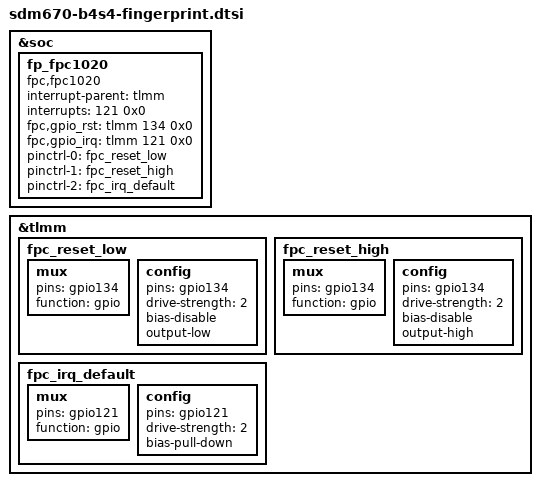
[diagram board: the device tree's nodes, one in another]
/* Copyright (c) 2018, The Linux Foundation. All rights reserved.
 *
 * This program is free software; you can redistribute it and/or modify
 * it under the terms of the GNU General Public License version 2 and
 * only version 2 as published by the Free Software Foundation.
 *
 * This program is distributed in the hope that it will be useful,
 * but WITHOUT ANY WARRANTY; without even the implied warranty of
 * MERCHANTABILITY or FITNESS FOR A PARTICULAR PURPOSE.  See the
 * GNU General Public License for more details.
 */

&soc {
	fp_fpc1020 {
		status ="ok";
		compatible = "fpc,fpc1020";
		interrupt-parent = <&tlmm>;
		interrupts = <121 0x0>;
		fpc,gpio_rst = <&tlmm 134 0x0>;
		fpc,gpio_irq = <&tlmm 121 0x0>;

		pinctrl-names = "fpc1020_reset_reset",
				"fpc1020_reset_active",
				"fpc1020_irq_active";

		pinctrl-0 = <&fpc_reset_low>;
		pinctrl-1 = <&fpc_reset_high>;
		pinctrl-2 = <&fpc_irq_default>;
	};
} ;

&tlmm {
	fpc_reset_low: fpc_reset_low {
		mux {
			pins = "gpio134";
			function = "gpio";
		};

		config {
			pins = "gpio134";
			drive-strength = <2>;
			bias-disable;
			output-low;
		};
	};

	fpc_reset_high: fpc_reset_high {
		mux {
			pins = "gpio134";
			function = "gpio";
		};

		config {
			pins = "gpio134";
			drive-strength = <2>;
			bias-disable;
			output-high;
		};
	};

	fpc_irq_default: fpc_irq_default {
		mux {
			pins = "gpio121";
			function = "gpio";
		};

	    config {
			pins = "gpio121";
			drive-strength = <2>;
			bias-pull-down;
		};
	};
};

